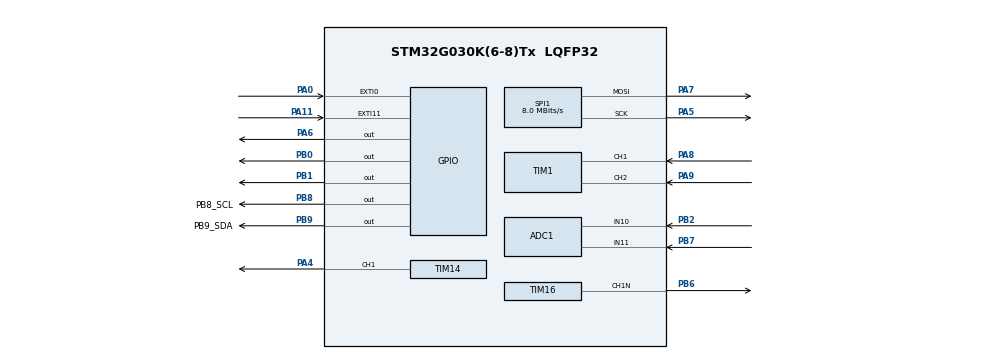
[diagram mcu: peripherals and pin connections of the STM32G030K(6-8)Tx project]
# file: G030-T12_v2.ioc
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ADC1.Channel-5\#ChannelRegularConversion=ADC_CHANNEL_10
ADC1.ClockPrescaler=ADC_CLOCK_SYNC_PCLK_DIV4
ADC1.ContinuousConvMode=DISABLE
ADC1.DiscontinuousConvMode=ENABLE
ADC1.EOCSelection=ADC_EOC_SINGLE_CONV
ADC1.NbrOfConversion=1
ADC1.NbrOfConversionFlag=1
ADC1.Rank-5\#ChannelRegularConversion=1
ADC1.SamplingTime-5\#ChannelRegularConversion=ADC_SAMPLINGTIME_COMMON_1
ADC1.SamplingTimeCommon1=ADC_SAMPLETIME_160CYCLES_5
ADC1.SamplingTimeCommon2=ADC_SAMPLETIME_160CYCLES_5
ADC1.SelectedChannel=ADC_CHANNEL_TEMPSENSOR|ADC_CHANNEL_VREFINT|ADC_CHANNEL_10|ADC_CHANNEL_11
ADC1.Sequencer=FULLY_CONFIGURABLE
ADC1.TriggerFrequencyMode=ADC_TRIGGER_FREQ_LOW
ADC1.master=1
Mcu.Family=STM32G0
Mcu.Name=STM32G030K(6-8)Tx
Mcu.Package=LQFP32
NVIC.TIM16_IRQn=true\:0\:0\:false\:false\:true\:true\:true\:true
PA0.GPIO_ModeDefaultEXTI=GPIO_MODE_EVT_FALLING
PA0.Signal=GPXTI0
PA11\ [PA9].Signal=GPXTI11
PA13.Mode=Serial_Wire
PA13.Signal=SYS_SWDIO
PA14-BOOT0.Mode=Serial_Wire
PA14-BOOT0.Signal=SYS_SWCLK
PA4.Signal=S_TIM14_CH1
PA5.Mode=TX_Only_Simplex_Unidirect_Master
PA5.Signal=SPI1_SCK
PA6.Signal=GPIO_Output
PA7.Mode=TX_Only_Simplex_Unidirect_Master
PA7.Signal=SPI1_MOSI
PA8.Signal=S_TIM1_CH1
PA9.Signal=S_TIM1_CH2
PB0.Signal=GPIO_Output
PB1.Signal=GPIO_Output
PB2.Signal=SharedAnalog_PB2
PB6.Mode=PWM Generation1 CH1N
PB6.Signal=TIM16_CH1N
PB7.Signal=SharedAnalog_PB7
PB8.GPIO_Label=PB8_SCL
PB8.GPIO_ModeDefaultOutputPP=GPIO_MODE_OUTPUT_OD
PB8.GPIO_PuPd=GPIO_NOPULL
PB8.GPIO_Speed=GPIO_SPEED_FREQ_LOW
PB8.Signal=GPIO_Output
PB9.GPIO_Label=PB9_SDA
PB9.GPIO_ModeDefaultOutputPP=GPIO_MODE_OUTPUT_OD
PB9.GPIO_PuPd=GPIO_NOPULL
PB9.GPIO_Speed=GPIO_SPEED_FREQ_LOW
PB9.Signal=GPIO_Output
ProjectManager.HeapSize=0x200
ProjectManager.StackSize=0x400
ProjectManager.TargetToolchain=MDK-ARM V5.32
RCC.ADCCLockSelection=RCC_ADCCLKSOURCE_HSI
RCC.ADCFreq_Value=16000000
RCC.AHBFreq_Value=64000000
RCC.CortexFreq_Value=64000000
RCC.EXTERNAL_CLOCK_VALUE=12288000
RCC.HCLKFreq_Value=64000000
RCC.HSE_VALUE=8000000
RCC.HSI_VALUE=16000000
RCC.LSE_VALUE=32768
RCC.SYSCLKFreq_VALUE=64000000
RCC.SYSCLKSource=RCC_SYSCLKSOURCE_PLLCLK
RCC.VCOOutputFreq_Value=128000000
SH.S_TIM14_CH1.0=TIM14_CH1,PWM Generation1 CH1
SH.S_TIM1_CH1.0=TIM1_CH1,Encoder_Interface
SH.S_TIM1_CH2.0=TIM1_CH2,Encoder_Interface
SH.SharedAnalog_PB2.0=GPIO_Analog
SH.SharedAnalog_PB2.1=ADC1_IN10,IN10
SH.SharedAnalog_PB7.0=GPIO_Analog
SH.SharedAnalog_PB7.1=ADC1_IN11,IN11
SPI1.BaudRatePrescaler=SPI_BAUDRATEPRESCALER_8
SPI1.CLKPhase=SPI_PHASE_2EDGE
SPI1.CLKPolarity=SPI_POLARITY_HIGH
SPI1.CalculateBaudRate=8.0 MBits/s
SPI1.Direction=SPI_DIRECTION_2LINES
SPI1.Mode=SPI_MODE_MASTER
SPI1.VirtualType=VM_MASTER
TIM14.AutoReloadPreload=TIM_AUTORELOAD_PRELOAD_ENABLE
TIM14.Channel=TIM_CHANNEL_1
TIM14.Period=249
TIM14.Prescaler=63
TIM14.Pulse=25
TIM16.AutoReloadPreload=TIM_AUTORELOAD_PRELOAD_ENABLE
TIM16.Channel=TIM_CHANNEL_1
TIM16.Period=9
TIM16.Prescaler=6399
TIM16.Pulse=500
TIM17.Period=0
TIM17.Prescaler=63
TIM3.AutoReloadPreload=TIM_AUTORELOAD_PRELOAD_ENABLE
TIM3.Period=1999
TIM3.Prescaler=63
VP_ADC1_TempSens_Input.Mode=IN-TempSens
VP_ADC1_Vref_Input.Mode=IN-Vrefint
VP_TIM14_VS_ClockSourceINT.Mode=Enable_Timer
VP_TIM16_VS_ClockSourceINT.Mode=Enable_Timer
VP_TIM17_VS_ClockSourceINT.Mode=Enable_Timer
VP_TIM3_VS_ClockSourceINT.Mode=Internal
board=custom

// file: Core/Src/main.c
/* USER CODE BEGIN Header */
/**
  ******************************************************************************
  * @file           : main.c
  * @brief          : Main program body (重构版本)
  ******************************************************************************
  * @attention
  *
  * Copyright (c) 2024 STMicroelectronics.
  * All rights reserved.
  *
  * This software is licensed under terms that can be found in the LICENSE file
  * in the root directory of this software component.
  * If no LICENSE file comes with this software, it is provided AS-IS.
  *
  ******************************************************************************
  */
/* USER CODE END Header */
#include "main.h"
#include "adc.h"
#include "spi.h"
#include "tim.h"
#include "gpio.h"

/* USER CODE BEGIN Includes */
#include "app_state_machine.h"
//#include "SEGGER_RTT.h"
/* USER CODE END Includes */

/* USER CODE BEGIN PV */
// 全局变量(供其他模块使用)
__IO uint32_t TIM16_Tick = 0;
uint32_t start_tick, cycle_time;
uint16_t Vin = 0;
/* USER CODE END PV */

void SystemClock_Config(void);

int main(void)
{

  /* MCU Configuration--------------------------------------------------------*/

  /* Reset of all peripherals, Initializes the Flash interface and the Systick. */
  LL_APB2_GRP1_EnableClock(LL_APB2_GRP1_PERIPH_SYSCFG);
  LL_APB1_GRP1_EnableClock(LL_APB1_GRP1_PERIPH_PWR);

  /* SysTick_IRQn interrupt configuration */
  NVIC_SetPriority(SysTick_IRQn, 3);

  /* Configure the system clock */
  SystemClock_Config();

  /* Initialize all configured peripherals */
  MX_GPIO_Init();
  MX_ADC1_Init();
  MX_SPI1_Init();
  MX_TIM1_Init();
  MX_TIM3_Init();
  MX_TIM17_Init();
  MX_TIM14_Init();
  MX_TIM16_Init();
  /* USER CODE BEGIN 2 */

  // 激活ADC
  Activate_ADC();

  // 启动TIM16用于系统时钟
  LL_TIM_EnableAllOutputs(TIM16);
  LL_TIM_EnableIT_CC1(TIM16);
  LL_TIM_CC_EnableChannel(TIM16, LL_TIM_CHANNEL_CH1N);
  LL_TIM_EnableCounter(TIM16);

  // 初始化应用状态机
  AppStateMachine_Init();

  /* USER CODE END 2 */

  /* Infinite loop */
  /* USER CODE BEGIN WHILE */
  while (1)
  {
		start_tick = TIM16_Tick;
    // 运行应用状态机
    AppStateMachine_Run();
		cycle_time = TIM16_Tick - start_tick;

    /* USER CODE END WHILE */

  }
}

void SystemClock_Config(void)
{
  LL_FLASH_SetLatency(LL_FLASH_LATENCY_2);
  while(LL_FLASH_GetLatency() != LL_FLASH_LATENCY_2)
  {
  }

  /* HSI configuration and activation */
  LL_RCC_HSI_Enable();
  while(LL_RCC_HSI_IsReady() != 1)
  {
  }

  /* Main PLL configuration and activation */
  LL_RCC_PLL_ConfigDomain_SYS(LL_RCC_PLLSOURCE_HSI, LL_RCC_PLLM_DIV_1, 8, LL_RCC_PLLR_DIV_2);
  LL_RCC_PLL_Enable();
  LL_RCC_PLL_EnableDomain_SYS();
  while(LL_RCC_PLL_IsReady() != 1)
  {
  }

  /* Set AHB prescaler*/
  LL_RCC_SetAHBPrescaler(LL_RCC_SYSCLK_DIV_1);

  /* Sysclk activation on the main PLL */
  LL_RCC_SetSysClkSource(LL_RCC_SYS_CLKSOURCE_PLL);
  while(LL_RCC_GetSysClkSource() != LL_RCC_SYS_CLKSOURCE_STATUS_PLL)
  {
  }

  /* Set APB1 prescaler*/
  LL_RCC_SetAPB1Prescaler(LL_RCC_APB1_DIV_1);

  LL_Init1msTick(64000000);

  /* Update CMSIS variable (which can be updated also through SystemCoreClockUpdate function) */
  LL_SetSystemCoreClock(64000000);
}

void Error_Handler(void)
{
  __disable_irq();
  while (1)
  {
  }
}
